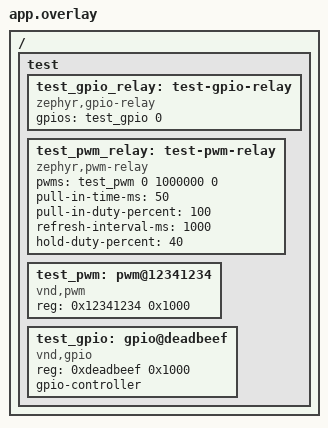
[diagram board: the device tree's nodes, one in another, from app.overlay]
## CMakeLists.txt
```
# Copyright (c) 2026 Siemens AG
# SPDX-License-Identifier: Apache-2.0

cmake_minimum_required(VERSION 3.28.0)
find_package(Zephyr REQUIRED HINTS $ENV{ZEPHYR_BASE})
project(build_all)

target_sources(app PRIVATE src/main.c)
```

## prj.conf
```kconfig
CONFIG_TEST=y
CONFIG_TEST_USERSPACE=y
CONFIG_SHELL=y
CONFIG_RELAY=y
CONFIG_RELAY_SHELL=y
```

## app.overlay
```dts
/*
 * Copyright (c) 2026 Siemens AG
 *
 * SPDX-License-Identifier: Apache-2.0
 *
 * Application overlay for testing driver builds
 *
 * Names in this file should be chosen in a way that won't conflict
 * with real-world devicetree nodes, to allow these tests to run on
 * (and be extended to test) real hardware.
 */

/ {
	test {
		#address-cells = <1>;
		#size-cells = <1>;

		test_gpio_relay: test-gpio-relay {
			compatible = "zephyr,gpio-relay";
			gpios = <&test_gpio 0 0>;
		};

		test_pwm_relay: test-pwm-relay {
			compatible = "zephyr,pwm-relay";
			pwms = <&test_pwm 0 1000000 0>;
			pull-in-time-ms = <50>;
			pull-in-duty-percent = <100>;
			refresh-interval-ms = <1000>;
			hold-duty-percent = <40>;
		};

		test_pwm: pwm@12341234 {
			compatible = "vnd,pwm";
			reg = <0x12341234 0x1000>;
			#pwm-cells = <3>;
			status = "okay";
		};

		test_gpio: gpio@deadbeef {
			compatible = "vnd,gpio";
			reg = <0xdeadbeef 0x1000>;
			gpio-controller;
			#gpio-cells = <0x2>;
			status = "okay";
		};
	};
};
```

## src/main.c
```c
/*
 * Copyright (c) 2026 Siemens AG
 *
 * SPDX-License-Identifier: Apache-2.0
 */

int main(void)
{
	return 0;
}
```
